# wdt_a register map
Vendor: Texas Instruments
Peripheral module from a debugger description file (folder MSP432).
Registers are 16-bit, read-write, no defined reset value unless marked. A register's access mark holds for its fields unless they carry their own. Offsets are as the file gives them; lines under a group give offsets from that group; [hi:lo] are bit positions; {n}, {i} and the like mark numbered series; 'fields as' and 'values as' point back to an identical list; <NAME> marks a mode.

## WDT_A
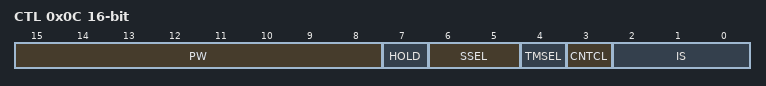
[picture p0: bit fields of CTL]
0x0C CTL — Watchdog Timer Control Register
  [15:8] PW — Watchdog timer password
  [7] HOLD — Watchdog timer hold
    0=HOLD__0 (Watchdog timer is not stopped); 1=HOLD__1 (Watchdog timer is stopped)
  [6:5] SSEL — Watchdog timer clock source select.
    0=SSEL__0 (SMCLK); 1=SSEL__1 (ACLK); 2=SSEL__2 (VLOCLK); 3=SSEL__3 (BCLK)
  [4] TMSEL — Watchdog timer mode select.
    0=TMSEL__0 (Watchdog mode); 1=TMSEL__1 (Interval timer mode)
  [3] CNTCL — Watchdog timer counter clear
    0=CNTCL__0 (No action); 1=CNTCL__1 (WDTCNT = 0000h)
  [2:0] IS — Watchdog timer interval select
    0=IS__0 (Watchdog clock source / (2^(31)) (18:12:16 at 32.768 kHz)); 1=IS__1 (Watchdog clock source /(2^(27)) (01:08:16 at 32.768 kHz)); 2=IS__2 (Watchdog clock source /(2^(23)) (00:04:16 at 32.768 kHz)); 3=IS__3 (Watchdog clock source /(2^(19)) (00:00:16 at 32.768 kHz)); 4=IS__4 (Watchdog clock source /(2^(15)) (1 s at 32.768 kHz)); 5=IS__5 (Watchdog clock source / (2^(13)) (250 ms at 32.768 kHz)); 6=IS__6 (Watchdog clock source / (2^(9)) (15.625 ms at 32.768 kHz)); 7=IS__7 (Watchdog clock source / (2^(6)) (1.95 ms at 32.768 kHz))
